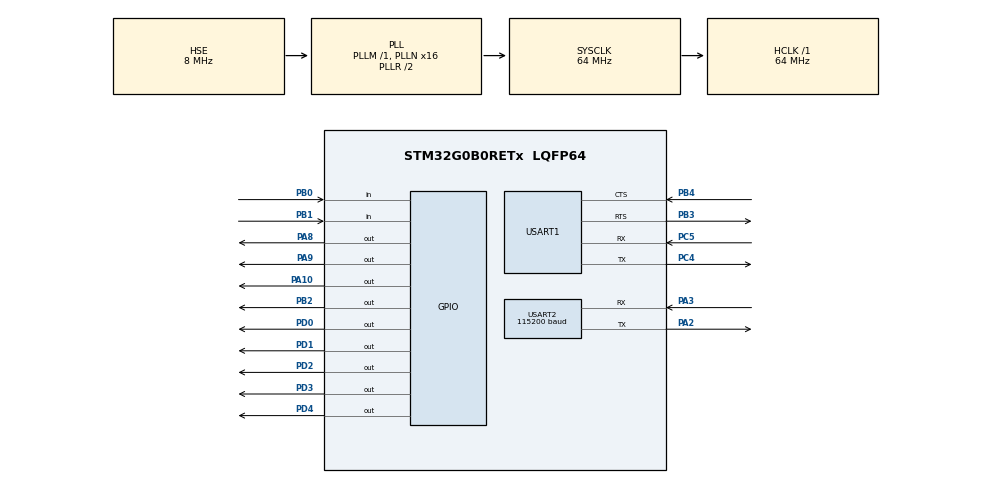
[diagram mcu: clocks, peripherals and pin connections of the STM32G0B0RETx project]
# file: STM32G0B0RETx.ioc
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Dma.Request0=USART1_RX
Dma.Request1=USART1_TX
Dma.USART1_RX.0.Direction=DMA_PERIPH_TO_MEMORY
Dma.USART1_RX.0.EventEnable=DISABLE
Dma.USART1_RX.0.Instance=DMA1_Channel1
Dma.USART1_RX.0.MemDataAlignment=DMA_MDATAALIGN_BYTE
Dma.USART1_RX.0.MemInc=DMA_MINC_ENABLE
Dma.USART1_RX.0.Mode=DMA_CIRCULAR
Dma.USART1_RX.0.PeriphDataAlignment=DMA_PDATAALIGN_BYTE
Dma.USART1_RX.0.PeriphInc=DMA_PINC_DISABLE
Dma.USART1_RX.0.Polarity=HAL_DMAMUX_REQ_GEN_RISING
Dma.USART1_RX.0.Priority=DMA_PRIORITY_VERY_HIGH
Dma.USART1_RX.0.RequestNumber=1
Dma.USART1_RX.0.SignalID=NONE
Dma.USART1_RX.0.SyncEnable=DISABLE
Dma.USART1_RX.0.SyncPolarity=HAL_DMAMUX_SYNC_NO_EVENT
Dma.USART1_RX.0.SyncRequestNumber=1
Dma.USART1_RX.0.SyncSignalID=NONE
Dma.USART1_TX.1.Direction=DMA_MEMORY_TO_PERIPH
Dma.USART1_TX.1.EventEnable=DISABLE
Dma.USART1_TX.1.Instance=DMA1_Channel2
Dma.USART1_TX.1.MemDataAlignment=DMA_MDATAALIGN_BYTE
Dma.USART1_TX.1.MemInc=DMA_MINC_ENABLE
Dma.USART1_TX.1.Mode=DMA_NORMAL
Dma.USART1_TX.1.PeriphDataAlignment=DMA_PDATAALIGN_BYTE
Dma.USART1_TX.1.PeriphInc=DMA_PINC_DISABLE
Dma.USART1_TX.1.Polarity=HAL_DMAMUX_REQ_GEN_RISING
Dma.USART1_TX.1.Priority=DMA_PRIORITY_VERY_HIGH
Dma.USART1_TX.1.RequestNumber=1
Dma.USART1_TX.1.SignalID=NONE
Dma.USART1_TX.1.SyncEnable=DISABLE
Dma.USART1_TX.1.SyncPolarity=HAL_DMAMUX_SYNC_NO_EVENT
Dma.USART1_TX.1.SyncRequestNumber=1
Dma.USART1_TX.1.SyncSignalID=NONE
IWDG.Prescaler=IWDG_PRESCALER_256
IWDG.Reload=4095
IWDG.Window=4095
Mcu.Family=STM32G0
Mcu.Name=STM32G0B0RETx
Mcu.Package=LQFP64
NVIC.DMA1_Channel1_IRQn=true\:3\:0\:true\:false\:true\:false\:true\:true
NVIC.DMA1_Channel2_3_IRQn=true\:3\:0\:true\:false\:true\:false\:true\:true
NVIC.TIM1_BRK_UP_TRG_COM_IRQn=true\:3\:0\:true\:false\:true\:false\:true\:true
NVIC.TimeBase=TIM1_BRK_UP_TRG_COM_IRQn
NVIC.TimeBaseIP=TIM1
NVIC.USART1_IRQn=true\:3\:0\:true\:false\:true\:true\:true\:true
NVIC.USART2_IRQn=true\:3\:0\:true\:false\:true\:true\:true\:true
PA10.GPIO_ModeDefaultOutputPP=GPIO_MODE_OUTPUT_OD
PA10.GPIO_PuPd=GPIO_PULLUP
PA10.GPIO_Speed=GPIO_SPEED_FREQ_VERY_HIGH
PA10.Signal=GPIO_Output
PA13.Mode=Serial_Wire
PA13.Signal=SYS_SWDIO
PA14-BOOT0.Mode=Serial_Wire
PA14-BOOT0.Signal=SYS_SWCLK
PA2.GPIO_Speed=GPIO_SPEED_FREQ_VERY_HIGH
PA2.Mode=Asynchronous
PA2.Signal=USART2_TX
PA3.GPIO_Speed=GPIO_SPEED_FREQ_VERY_HIGH
PA3.Mode=Asynchronous
PA3.Signal=USART2_RX
PA8.GPIO_PuPd=GPIO_PULLUP
PA8.Signal=GPIO_Output
PA9.GPIO_ModeDefaultOutputPP=GPIO_MODE_OUTPUT_OD
PA9.GPIO_PuPd=GPIO_PULLUP
PA9.GPIO_Speed=GPIO_SPEED_FREQ_VERY_HIGH
PA9.Signal=GPIO_Output
PB0.GPIO_PuPd=GPIO_NOPULL
PB0.Signal=GPIO_Input
PB1.Signal=GPIO_Input
PB2.Signal=GPIO_Output
PB3.Mode=CTS_RTS
PB3.Signal=USART1_RTS
PB4.Mode=CTS_RTS
PB4.Signal=USART1_CTS
PC4.GPIO_Speed=GPIO_SPEED_FREQ_VERY_HIGH
PC4.Mode=Asynchronous
PC4.PinState=GPIO_PIN_SET
PC4.Signal=USART1_TX
PC5.GPIO_Speed=GPIO_SPEED_FREQ_VERY_HIGH
PC5.Mode=Asynchronous
PC5.PinState=GPIO_PIN_SET
PC5.Signal=USART1_RX
PD0.GPIO_PuPd=GPIO_PULLDOWN
PD0.Signal=GPIO_Output
PD1.GPIO_PuPd=GPIO_PULLDOWN
PD1.Signal=GPIO_Output
PD2.GPIO_PuPd=GPIO_PULLDOWN
PD2.Signal=GPIO_Output
PD3.GPIO_PuPd=GPIO_PULLDOWN
PD3.Signal=GPIO_Output
PD4.GPIO_PuPd=GPIO_PULLDOWN
PD4.Signal=GPIO_Output
PF0-OSC_IN\ (PF0).Mode=HSE-External-Oscillator
PF0-OSC_IN\ (PF0).Signal=RCC_OSC_IN
PF1-OSC_OUT\ (PF1).Mode=HSE-External-Oscillator
PF1-OSC_OUT\ (PF1).Signal=RCC_OSC_OUT
ProjectManager.HeapSize=0x200
ProjectManager.StackSize=0x400
ProjectManager.TargetToolchain=Makefile
RCC.ADCFreq_Value=64000000
RCC.AHBFreq_Value=64000000
RCC.CodegenConfigPeriph=true
RCC.CortexFreq_Value=64000000
RCC.EXTERNAL_CLOCK_VALUE=48000
RCC.HCLKFreq_Value=64000000
RCC.HSE_VALUE=8000000
RCC.HSI_VALUE=16000000
RCC.LSE_VALUE=32768
RCC.PLLN=16
RCC.PLLSourceVirtual=RCC_PLLSOURCE_HSE
RCC.SYSCLKFreq_VALUE=64000000
RCC.SYSCLKSource=RCC_SYSCLKSOURCE_PLLCLK
RCC.USBFreq_Value=64000000
RCC.VCOOutputFreq_Value=128000000
USART1.VirtualMode-Asynchronous=VM_ASYNC
USART2.BaudRate=115200
USART2.FIFOMode=FIFOMODE_DISABLE
USART2.OverrunDisableParam=ADVFEATURE_OVERRUN_ENABLE
USART2.VirtualMode-Asynchronous=VM_ASYNC
VP_IWDG_VS_IWDG.Mode=IWDG_Activate
VP_RTC_VS_RTC_Activate.Mode=RTC_Enabled
VP_SYS_VS_DBSignals.Mode=DisableDeadBatterySignals
VP_SYS_VS_tim1.Mode=TIM1
board=custom

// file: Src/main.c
/* USER CODE BEGIN Header */
/**
 ******************************************************************************
 * @file           : main.c
 * @brief          : Main program body
 ******************************************************************************
 * @attention
 *
 * Copyright (c) 2023 STMicroelectronics.
 * All rights reserved.
 *
 * This software is licensed under terms that can be found in the LICENSE file
 * in the root directory of this software component.
 * If no LICENSE file comes with this software, it is provided AS-IS.
 *
 ******************************************************************************
 */
/* USER CODE END Header */
#include "main.h"
#include "dma.h"
#include "iwdg.h"
#include "rtc.h"
#include "usart.h"
#include "gpio.h"

/* USER CODE BEGIN Includes */
#include "FreeRTOS.h"
#include "task.h"
/* USER CODE END Includes */

void SystemClock_Config(void);

/* USER CODE BEGIN 0 */
#if configAPPLICATION_ALLOCATED_HEAP
uint8_t ucHeap[configTOTAL_HEAP_SIZE];
#endif
/* USER CODE END 0 */

int main(void)
{

  /* MCU Configuration--------------------------------------------------------*/

  /* Reset of all peripherals, Initializes the Flash interface and the Systick. */
  HAL_Init();

  /* Configure the system clock */
  SystemClock_Config();

  /* Initialize all configured peripherals */
  MX_GPIO_Init();
  MX_DMA_Init();
  MX_USART1_UART_Init();
  MX_USART2_UART_Init();
  MX_RTC_Init();
  MX_IWDG_Init();
  /* USER CODE BEGIN 2 */
  extern void app_main(void* p);
  xTaskCreate(app_main, "main", 2048, NULL, 5, NULL);
  vTaskStartScheduler();
  /* USER CODE END 2 */

  /* Infinite loop */
    while (1) {

    }
}

void SystemClock_Config(void)
{
  RCC_OscInitTypeDef RCC_OscInitStruct = {0};
  RCC_ClkInitTypeDef RCC_ClkInitStruct = {0};

  /** Configure the main internal regulator output voltage
  */
  HAL_PWREx_ControlVoltageScaling(PWR_REGULATOR_VOLTAGE_SCALE1);

  /** Initializes the RCC Oscillators according to the specified parameters
  * in the RCC_OscInitTypeDef structure.
  */
  RCC_OscInitStruct.OscillatorType = RCC_OSCILLATORTYPE_LSI|RCC_OSCILLATORTYPE_HSE;
  RCC_OscInitStruct.HSEState = RCC_HSE_ON;
  RCC_OscInitStruct.LSIState = RCC_LSI_ON;
  RCC_OscInitStruct.PLL.PLLState = RCC_PLL_ON;
  RCC_OscInitStruct.PLL.PLLSource = RCC_PLLSOURCE_HSE;
  RCC_OscInitStruct.PLL.PLLM = RCC_PLLM_DIV1;
  RCC_OscInitStruct.PLL.PLLN = 16;
  RCC_OscInitStruct.PLL.PLLP = RCC_PLLP_DIV2;
  RCC_OscInitStruct.PLL.PLLQ = RCC_PLLQ_DIV2;
  RCC_OscInitStruct.PLL.PLLR = RCC_PLLR_DIV2;
  if (HAL_RCC_OscConfig(&RCC_OscInitStruct) != HAL_OK)
  {
    Error_Handler();
  }

  /** Initializes the CPU, AHB and APB buses clocks
  */
  RCC_ClkInitStruct.ClockType = RCC_CLOCKTYPE_HCLK|RCC_CLOCKTYPE_SYSCLK
                              |RCC_CLOCKTYPE_PCLK1;
  RCC_ClkInitStruct.SYSCLKSource = RCC_SYSCLKSOURCE_PLLCLK;
  RCC_ClkInitStruct.AHBCLKDivider = RCC_SYSCLK_DIV1;
  RCC_ClkInitStruct.APB1CLKDivider = RCC_HCLK_DIV1;

  if (HAL_RCC_ClockConfig(&RCC_ClkInitStruct, FLASH_LATENCY_2) != HAL_OK)
  {
    Error_Handler();
  }
}

void HAL_TIM_PeriodElapsedCallback(TIM_HandleTypeDef *htim)
{
  if (htim->Instance == TIM1) {
    HAL_IncTick();
  }
}

void Error_Handler(void)
{
    __disable_irq();
    while (1) {
    }
}
